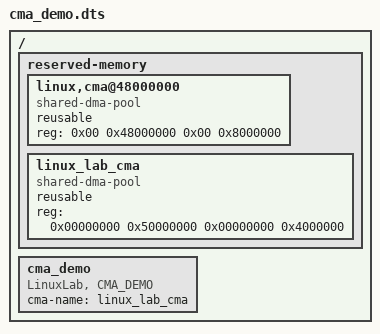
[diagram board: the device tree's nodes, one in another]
/*
 *  cma_demo.dts
 *  
 *  (C) 2024.12.12 <hkdywg@163.com>
 *
 *  This program is free software; you can redistribute it and/r modify
 *  it under the terms of the GNU General Public License version 2 as
 *  published by the Free Software Foundation.
 * */

/ {
	reserved-memory {
		#address-cells = <2>;
		#size-cells = <2>;
		ranges;

		linux,cma@48000000 {
			compatible = "shared-dma-pool";
			reusable;
			reg = <0x00 0x48000000 0x00 0x8000000>;
		};

		linux_lab_cma {
			compatible = "shared-dma-pool";
			reusable;
			reg = <0x00000000 0x50000000 0x00000000 0x4000000>;
		};
	};

    cma_demo {
    	compatible = "LinuxLab, CMA_DEMO";
    	status = "okay";
		cma-name = "linux_lab_cma";
    };  
};
